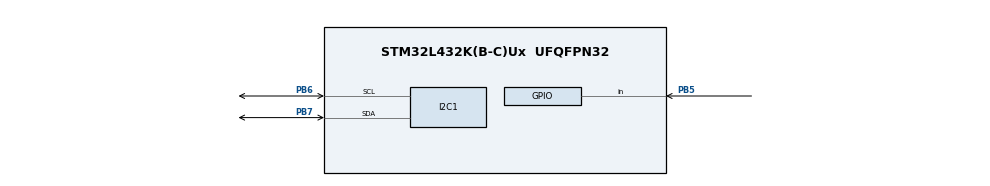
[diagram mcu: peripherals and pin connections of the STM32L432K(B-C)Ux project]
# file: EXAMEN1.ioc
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Mcu.Family=STM32L4
Mcu.Name=STM32L432K(B-C)Ux
Mcu.Package=UFQFPN32
NVIC.PriorityGroup=NVIC_PRIORITYGROUP_4
PB5.Signal=GPIO_Input
PB6.Mode=I2C
PB6.Signal=I2C1_SCL
PB7.Mode=I2C
PB7.Signal=I2C1_SDA
ProjectManager.HeapSize=0x200
ProjectManager.StackSize=0x400
ProjectManager.TargetToolchain=STM32CubeIDE
RCC.HSE_VALUE=8000000
RCC.HSI48_VALUE=48000000
RCC.HSI_VALUE=16000000
RCC.LSE_VALUE=32768
RCC.MSI_VALUE=4000000
RCC.VCOOutputFreq_Value=32000000
board=custom

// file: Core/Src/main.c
/* USER CODE BEGIN Header */
/**
  ******************************************************************************
  * @file           : main.c
  * @brief          : Main program body
  ******************************************************************************
  * @attention
  *
  * <h2><center>&copy; Copyright (c) 2022 STMicroelectronics.
  * All rights reserved.</center></h2>
  *
  * This software component is licensed by ST under BSD 3-Clause license,
  * the "License"; You may not use this file except in compliance with the
  * License. You may obtain a copy of the License at:
  *                        opensource.org/licenses/BSD-3-Clause
  *
  ******************************************************************************
  */
/* USER CODE END Header */
#include "main.h"

/* USER CODE BEGIN Includes */
#define SLAVE_ADDRESS_LCD 0x4E
/* USER CODE END Includes */

I2C_HandleTypeDef hi2c1;

void SystemClock_Config(void);
static void MX_GPIO_Init(void);
static void MX_I2C1_Init(void);

int main(void)
{

  /* MCU Configuration--------------------------------------------------------*/

  /* Reset of all peripherals, Initializes the Flash interface and the Systick. */
  HAL_Init();

  /* Configure the system clock */
  SystemClock_Config();

  /* Initialize all configured peripherals */
  MX_GPIO_Init();
  MX_I2C1_Init();

  /* Infinite loop */
  while (1)
  {
	  lcd_send_string("hola_mundo");
  }
}

void SystemClock_Config(void)
{
  RCC_OscInitTypeDef RCC_OscInitStruct = {0};
  RCC_ClkInitTypeDef RCC_ClkInitStruct = {0};
  RCC_PeriphCLKInitTypeDef PeriphClkInit = {0};

  /** Initializes the RCC Oscillators according to the specified parameters
  * in the RCC_OscInitTypeDef structure.
  */
  RCC_OscInitStruct.OscillatorType = RCC_OSCILLATORTYPE_MSI;
  RCC_OscInitStruct.MSIState = RCC_MSI_ON;
  RCC_OscInitStruct.MSICalibrationValue = 0;
  RCC_OscInitStruct.MSIClockRange = RCC_MSIRANGE_6;
  RCC_OscInitStruct.PLL.PLLState = RCC_PLL_NONE;
  if (HAL_RCC_OscConfig(&RCC_OscInitStruct) != HAL_OK)
  {
    Error_Handler();
  }
  /** Initializes the CPU, AHB and APB buses clocks
  */
  RCC_ClkInitStruct.ClockType = RCC_CLOCKTYPE_HCLK|RCC_CLOCKTYPE_SYSCLK
                              |RCC_CLOCKTYPE_PCLK1|RCC_CLOCKTYPE_PCLK2;
  RCC_ClkInitStruct.SYSCLKSource = RCC_SYSCLKSOURCE_MSI;
  RCC_ClkInitStruct.AHBCLKDivider = RCC_SYSCLK_DIV1;
  RCC_ClkInitStruct.APB1CLKDivider = RCC_HCLK_DIV1;
  RCC_ClkInitStruct.APB2CLKDivider = RCC_HCLK_DIV1;

  if (HAL_RCC_ClockConfig(&RCC_ClkInitStruct, FLASH_LATENCY_0) != HAL_OK)
  {
    Error_Handler();
  }
  PeriphClkInit.PeriphClockSelection = RCC_PERIPHCLK_I2C1;
  PeriphClkInit.I2c1ClockSelection = RCC_I2C1CLKSOURCE_PCLK1;
  if (HAL_RCCEx_PeriphCLKConfig(&PeriphClkInit) != HAL_OK)
  {
    Error_Handler();
  }
  /** Configure the main internal regulator output voltage
  */
  if (HAL_PWREx_ControlVoltageScaling(PWR_REGULATOR_VOLTAGE_SCALE1) != HAL_OK)
  {
    Error_Handler();
  }
}

static void MX_I2C1_Init(void)
{

  hi2c1.Instance = I2C1;
  hi2c1.Init.Timing = 0x00000E14;
  hi2c1.Init.OwnAddress1 = 0;
  hi2c1.Init.AddressingMode = I2C_ADDRESSINGMODE_7BIT;
  hi2c1.Init.DualAddressMode = I2C_DUALADDRESS_DISABLE;
  hi2c1.Init.OwnAddress2 = 0;
  hi2c1.Init.OwnAddress2Masks = I2C_OA2_NOMASK;
  hi2c1.Init.GeneralCallMode = I2C_GENERALCALL_DISABLE;
  hi2c1.Init.NoStretchMode = I2C_NOSTRETCH_DISABLE;
  if (HAL_I2C_Init(&hi2c1) != HAL_OK)
  {
    Error_Handler();
  }
  /** Configure Analogue filter
  */
  if (HAL_I2CEx_ConfigAnalogFilter(&hi2c1, I2C_ANALOGFILTER_ENABLE) != HAL_OK)
  {
    Error_Handler();
  }
  /** Configure Digital filter
  */
  if (HAL_I2CEx_ConfigDigitalFilter(&hi2c1, 0) != HAL_OK)
  {
    Error_Handler();
  }

}

static void MX_GPIO_Init(void)
{
  GPIO_InitTypeDef GPIO_InitStruct = {0};

  /* GPIO Ports Clock Enable */
  __HAL_RCC_GPIOB_CLK_ENABLE();

  /*Configure GPIO pin : PB5 */
  GPIO_InitStruct.Pin = GPIO_PIN_5;
  GPIO_InitStruct.Mode = GPIO_MODE_INPUT;
  GPIO_InitStruct.Pull = GPIO_NOPULL;
  HAL_GPIO_Init(GPIOB, &GPIO_InitStruct);

}

/* USER CODE BEGIN 4 */
void lcd_send_cmd (char cmd)
{
  char data_u, data_l;
	uint8_t data_t[4];
	data_u = (cmd&0xf0);
	data_l = ((cmd<<4)&0xf0);
	data_t[0] = data_u|0x0C;  //en=1, rs=0
	data_t[1] = data_u|0x08;  //en=0, rs=0
	data_t[2] = data_l|0x0C;  //en=1, rs=0
	data_t[3] = data_l|0x08;  //en=0, rs=0
	HAL_I2C_Master_Transmit (&hi2c1, SLAVE_ADDRESS_LCD,(uint8_t *) data_t, 4, 100);
}

void lcd_send_data (char data)
{
	char data_u, data_l;
	uint8_t data_t[4];
	data_u = (data&0xf0);
	data_l = ((data<<4)&0xf0);
	data_t[0] = data_u|0x0D;  //en=1, rs=1
	data_t[1] = data_u|0x09;  //en=0, rs=1
	data_t[2] = data_l|0x0D;  //en=1, rs=1
	data_t[3] = data_l|0x09;  //en=0, rs=1
	HAL_I2C_Master_Transmit (&hi2c1, SLAVE_ADDRESS_LCD,(uint8_t *) data_t, 4, 100);
}

void lcd_send_string (char *str)
{
	while (*str) lcd_send_data (*str++);
}
/* USER CODE END 4 */

void Error_Handler(void)
{
  __disable_irq();
  while (1)
  {
  }
}

/************************ (C) COPYRIGHT STMicroelectronics *****END OF FILE****/
